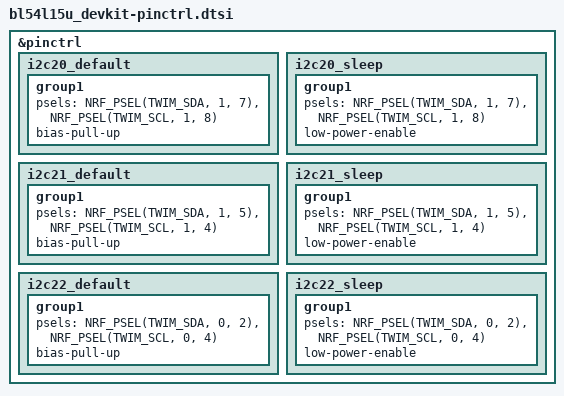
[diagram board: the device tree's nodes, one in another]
/*
 * Pin control for BL54L15u DevKit
 */

&pinctrl {
	/* I2C20 for NPM1304 PMIC (0x6B): SDA=P1.07, SCL=P1.08 */
	i2c20_default: i2c20_default {
		group1 {
			psels = <NRF_PSEL(TWIM_SDA, 1, 7)>,
				<NRF_PSEL(TWIM_SCL, 1, 8)>;
			bias-pull-up;
		};
	};

	i2c20_sleep: i2c20_sleep {
		group1 {
			psels = <NRF_PSEL(TWIM_SDA, 1, 7)>,
				<NRF_PSEL(TWIM_SCL, 1, 8)>;
			low-power-enable;
		};
	};

	/* I2C21 for Qwiic J1: SDA=P1.05, SCL=P1.04 */
	i2c21_default: i2c21_default {
		group1 {
			psels = <NRF_PSEL(TWIM_SDA, 1, 5)>,
				<NRF_PSEL(TWIM_SCL, 1, 4)>;
			bias-pull-up;
		};
	};

	i2c21_sleep: i2c21_sleep {
		group1 {
			psels = <NRF_PSEL(TWIM_SDA, 1, 5)>,
				<NRF_PSEL(TWIM_SCL, 1, 4)>;
			low-power-enable;
		};
	};

	/* I2C22 for Qwiic J8: SDA=P0.02, SCL=P0.04 */
	i2c22_default: i2c22_default {
		group1 {
			psels = <NRF_PSEL(TWIM_SDA, 0, 2)>,
				<NRF_PSEL(TWIM_SCL, 0, 4)>;
			bias-pull-up;
		};
	};

	i2c22_sleep: i2c22_sleep {
		group1 {
			psels = <NRF_PSEL(TWIM_SDA, 0, 2)>,
				<NRF_PSEL(TWIM_SCL, 0, 4)>;
			low-power-enable;
		};
	};
};
